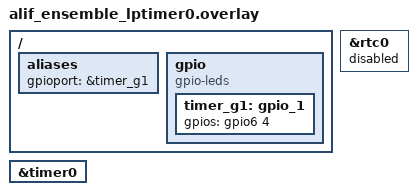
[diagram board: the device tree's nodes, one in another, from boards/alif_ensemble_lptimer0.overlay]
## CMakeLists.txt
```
cmake_minimum_required(VERSION 3.20.0)

find_package(Zephyr REQUIRED HINTS $ENV{ZEPHYR_BASE})
project(lptimer)

target_sources(app PRIVATE src/test_counter.c)
if(CONFIG_BUILD_WITH_TFM)
  target_include_directories(app PRIVATE
    $<TARGET_PROPERTY:tfm,TFM_BINARY_DIR>/api_ns/interface/include
  )
endif()
```

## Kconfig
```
# Config for counter alarm sample

# Copyright (c) 2019 Nordic Semiconductor ASA
# SPDX-License-Identifier: Apache-2.0

config LP_EXT
	bool "To Test LP-EXT"
	default n

config LP_CAS
	bool "To Test LP-CAS"
	default n

config LP_128K
	bool "To Test LP-128K"
	default n

config LPTIMER0_CLOCK_SOURCE_CASCADE
	bool "Enable cascade mode for LPTIMER0 (LPTIMER0+LPTIMER1)"
	default n

config LPTIMER1_CLOCK_SOURCE_CASCADE
	bool "Enable cascade mode for LPTIMER1 (LPTIMER1+LPTIMER2)"
	default n

config LPTIMER3_CLOCK_SOURCE_CASCADE
	bool "Enable cascade mode for LPTIMER3 (LPTIMER3+LPTIMER4)"
	default n

source "Kconfig.zephyr"
```

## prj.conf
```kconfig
CONFIG_PRINTK=y
CONFIG_COUNTER=y
CONFIG_ZTEST=y
CONFIG_COUNTER_SNPS_DW=y
CONFIG_COUNTER_RTC_SNPS_DW=n
CONFIG_SPIN_VALIDATE=n
```

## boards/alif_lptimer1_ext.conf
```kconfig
CONFIG_LPTIMER1_EXT_CLK_FREQ=1
```

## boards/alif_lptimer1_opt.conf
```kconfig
#CONFIG_LPTIMER1_EXT_CLK_FREQ=0
CONFIG_LPTIMER1_OUTPUT_TOGGLE=y
```

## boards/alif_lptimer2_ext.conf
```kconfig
CONFIG_LPTIMER2_EXT_CLK_FREQ=1
```

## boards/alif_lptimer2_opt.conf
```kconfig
CONFIG_LPTIMER2_EXT_CLK_FREQ=0
CONFIG_LPTIMER2_OUTPUT_TOGGLE=y
```

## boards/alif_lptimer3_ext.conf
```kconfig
CONFIG_LPTIMER3_EXT_CLK_FREQ=1
```

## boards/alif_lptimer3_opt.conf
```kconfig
# Copyright (c) 2024 Alif Semiconductor
#
# SPDX-License-Identifier: Apache-2.0

CONFIG_LPTIMER3_EXT_CLK_FREQ=0
CONFIG_LPTIMER3_OUTPUT_TOGGLE=y
```

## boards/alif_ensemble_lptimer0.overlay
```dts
/* Copyright Alif Semiconductor - All Rights Reserved.
 * Use, distribution and modification of this code is permitted under the
 * terms stated in the Alif Semiconductor Software License Agreement
 *
 * You should have received a copy of the Alif Semiconductor Software
 * License Agreement with this file. If not, please write to:
 * contact@alifsemi.com, or visit: https://alifsemi.com/license
 */
/ {
	aliases {
		gpioport = &timer_g1;
	};

	gpio {
		compatible = "gpio-leds";
		timer_g1: gpio_1 {
			gpios = <&gpio6 4 0>;
		};
	};
};
/*
 * Enabling lptimer & disabling rtc for this sample application
 */

&timer0 {
	status = "okay";
};

&rtc0 {
	status = "disabled";
};
```

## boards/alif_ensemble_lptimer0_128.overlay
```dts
/* Copyright Alif Semiconductor - All Rights Reserved.
 * Use, distribution and modification of this code is permitted under the
 * terms stated in the Alif Semiconductor Software License Agreement
 *
 * You should have received a copy of the Alif Semiconductor Software
 * License Agreement with this file. If not, please write to:
 * contact@alifsemi.com, or visit: https://alifsemi.com/license
 */
#include <zephyr/dt-bindings/clock/alif_ensemble_clocks.h>
/ {
	aliases {
		gpioport = &timer_g1;
	};

	gpio {
		compatible = "gpio-leds";
		timer_g1: gpio_1 {
			gpios = <&gpio6 4 0>;
		};
	};
};

/*
 * Enabling lptimer & disabling rtc for this sample application
 */

&timer0 {
	clocks = <&clockctrl ALIF_LPTIMER0_128K_CLK>;
	status = "okay";
};

&rtc0 {
	status = "disabled";
};
```

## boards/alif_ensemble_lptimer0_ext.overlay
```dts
/* Copyright Alif Semiconductor - All Rights Reserved.
 * Use, distribution and modification of this code is permitted under the
 * terms stated in the Alif Semiconductor Software License Agreement
 *
 * You should have received a copy of the Alif Semiconductor Software
 * License Agreement with this file. If not, please write to:
 * contact@alifsemi.com, or visit: https://alifsemi.com/license
 */
/ {
	aliases {
		gpioport = &timer_g1;
	};

	gpio {
		compatible = "gpio-leds";
		timer_g1: gpio_1 {
			gpios = <&gpio6 4 0>;
		};
	};
};
/*
 * Enabling lptimer & disabling rtc for this sample application
 */

&timer0 {
	clocks = <&clockctrl ALIF_LPTIMER0_LPTMR0_IO_PIN>;
	status = "okay";
};


&rtc0 {
	status = "disabled";
};
```

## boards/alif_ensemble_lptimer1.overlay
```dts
/* Copyright Alif Semiconductor - All Rights Reserved.
 * Use, distribution and modification of this code is permitted under the
 * terms stated in the Alif Semiconductor Software License Agreement
 *
 * You should have received a copy of the Alif Semiconductor Software
 * License Agreement with this file. If not, please write to:
 * contact@alifsemi.com, or visit: https://alifsemi.com/license
 */
/ {
	aliases {
		gpioport = &timer_g1;
	};

	gpio {
		compatible = "gpio-leds";
		timer_g1: gpio_1 {
			gpios = <&gpio6 2 0>;
		};
	};
};
/*
 * Enabling lptimer & disabling rtc for this sample application
 */

&timer1 {
	status = "okay";
};

&rtc0 {
	status = "disabled";
};
```

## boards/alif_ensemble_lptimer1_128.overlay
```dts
/* Copyright Alif Semiconductor - All Rights Reserved.
 * Use, distribution and modification of this code is permitted under the
 * terms stated in the Alif Semiconductor Software License Agreement
 *
 * You should have received a copy of the Alif Semiconductor Software
 * License Agreement with this file. If not, please write to:
 * contact@alifsemi.com, or visit: https://alifsemi.com/license
 */
#include <zephyr/dt-bindings/clock/alif_ensemble_clocks.h>
/ {
	aliases {
		gpioport = &timer_g1;
	};

	gpio {
		compatible = "gpio-leds";
		timer_g1: gpio_1 {
			gpios = <&gpio6 4 0>;
		};
	};
};
/*
 * Enabling lptimer & disabling rtc for this sample application
 */

&timer1 {
	clocks = <&clockctrl ALIF_LPTIMER1_128K_CLK>;
	status = "okay";
};

&rtc0 {
	status = "disabled";
};
```

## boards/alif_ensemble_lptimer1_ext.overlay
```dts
/* Copyright Alif Semiconductor - All Rights Reserved.
 * Use, distribution and modification of this code is permitted under the
 * terms stated in the Alif Semiconductor Software License Agreement
 *
 * You should have received a copy of the Alif Semiconductor Software
 * License Agreement with this file. If not, please write to:
 * contact@alifsemi.com, or visit: https://alifsemi.com/license
 */
/ {
	aliases {
		gpioport = &timer_g1;
	};

	gpio {
		compatible = "gpio-leds";
		timer_g1: gpio_1 {
			gpios = <&gpio6 4 0>;
		};
	};
};
/*
 * Enabling lptimer & disabling rtc for this sample application
 * 10Khz -->10000
 */

&timer1 {
	clocks = <&clockctrl ALIF_LPTIMER1_LPTMR1_IO_PIN >;
	status = "okay";
};

&rtc0 {
	status = "disabled";
};
```

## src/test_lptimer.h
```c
/* Copyright Alif Semiconductor - All Rights Reserved.
 * Use, distribution and modification of this code is permitted under the
 * terms stated in the Alif Semiconductor Software License Agreement
 *
 * You should have received a copy of the Alif Semiconductor Software
 * License Agreement with this file. If not, please write to:
 * contact@alifsemi.com, or visit: https://alifsemi.com/license
 */

#ifndef TEST_LPTIMER_H_
#define TEST_LPTIMER_H_

#include <zephyr/drivers/counter.h>
#include <zephyr/ztest.h>
#include <zephyr/kernel.h>
#include <zephyr/logging/log.h>
#include <zephyr/device.h>
#include <zephyr/drivers/gpio.h>
#ifdef CONFIG_PM
#include <zephyr/pm/pm.h>
#include <zephyr/pm/state.h>
#endif

/* External declarations for variables defined in test_counter.c */
extern struct k_sem top_cnt_sem;
extern volatile uint32_t top_cnt;
extern struct k_sem alarm_cnt_sem;
extern volatile uint32_t alarm_cnt;
extern struct counter_alarm_cfg alarm_cfg;
extern struct counter_alarm_cfg alarm_cfg2;
extern void *exp_user_data;

#define DOWN_COUNTER 0

/*Delay in microseconds i.e 2 sec*/
#define DELAY 2000000

/*Delay in microseconds i.e 5 sec*/
#define DELAY1 5000000
#define DELAY_EXTERNAL 4000000
/*Delay is 0.0005*/
#define EXTERNALDELAY 10000000
#define LPTIMER_MAX_CHANNELS 4

#define TICKS_PER_SEC 32768
#define ALARM_CHANNEL_ID 0
#define LED0_NODE DT_ALIAS(led0)

/* 1000 msec = 1 sec */
#define SLEEP_TIME_MS   1000

#define GPIO_NODE DT_ALIAS(gpioport)

#define INT_ITER 2
#define STRESS_TEST_COUNT 3

#define DEVICE_DT_GET_AND_COMMA(node_id) DEVICE_DT_GET(node_id),
/* Generate a list of devices for all instances of the "compat" */
#define DEVS_FOR_DT_COMPAT(compat) \
	DT_FOREACH_STATUS_OKAY(compat, DEVICE_DT_GET_AND_COMMA)

#define TIMER0 DT_NODELABEL(timer0)
#define TIMER1 DT_NODELABEL(timer1)
#define TIMER2 DT_NODELABEL(timer2)
#define TIMER3 DT_NODELABEL(timer3)

#endif /* TEST_LPTIMER_H_ */
```
